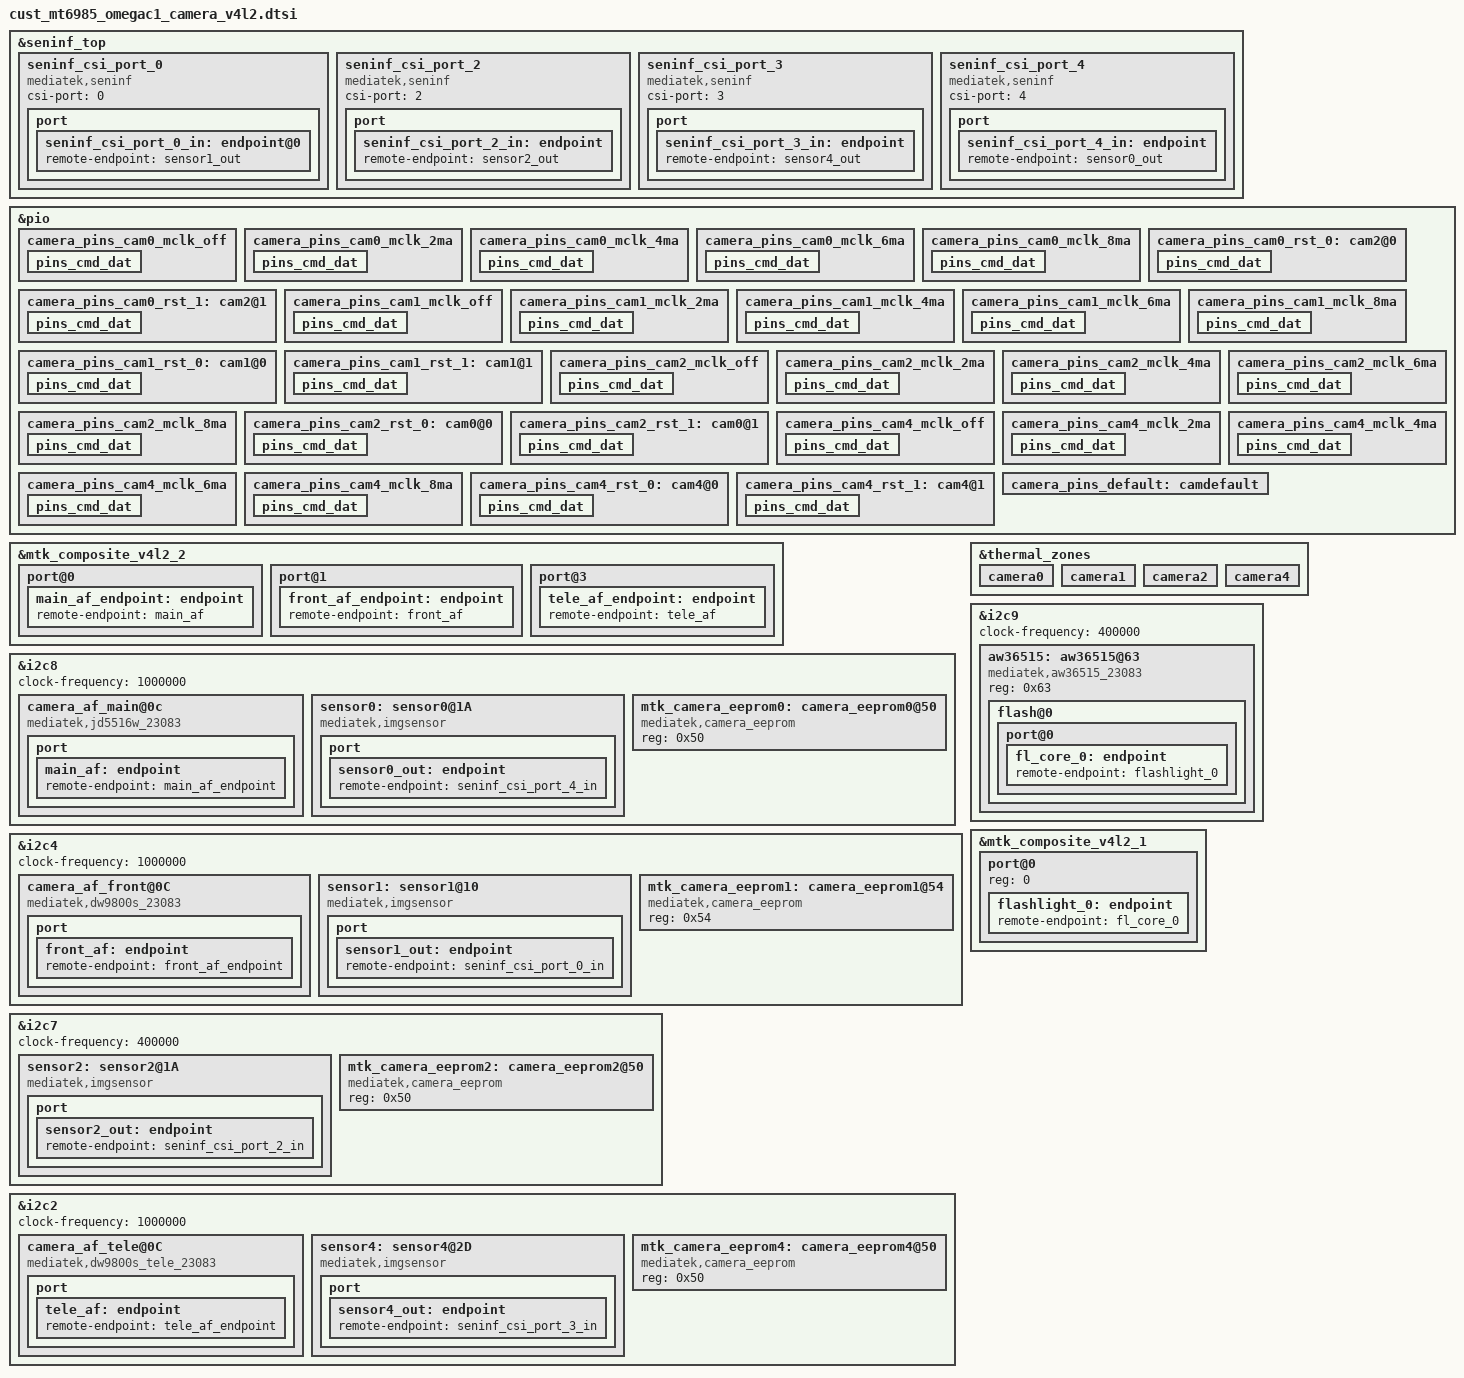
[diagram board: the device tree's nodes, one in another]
// SPDX-License-Identifier: GPL-2.0
/* Copyright (c) 2020 MediaTek Inc. */

#include <dt-bindings/clock/mt6985-clk.h>
#include "mediatek/omegac1-regulator.dtsi"

&seninf_top {
		seninf_csi_port_0: seninf_csi_port_0 {
			compatible = "mediatek,seninf";
			csi-port = "0";
#if 0
			nvmem-cells = <&csi_efuse0>;
			nvmem-cell-names = "rg_csi";
#endif
			port {
				seninf_csi_port_0_in: endpoint@0 {
					remote-endpoint = <&sensor1_out>; //front camera
				};
			};
		};

//		seninf_csi_port_1: seninf_csi_port_1 {
//			compatible = "mediatek,seninf";
//			csi-port = "1";
//#if 0
//			nvmem-cells = <&csi_efuse1>;
//			nvmem-cell-names = "rg_csi";
//#endif
//			port {
//			 	seninf_csi_port_1_in: endpoint {
//			 		remote-endpoint = <&sensor4_out>;
//			 	};
//			 };
//		};

		seninf_csi_port_2: seninf_csi_port_2 {
			compatible = "mediatek,seninf";
			csi-port = "2";
#if 0
			nvmem-cells = <&csi_efuse2>;
			nvmem-cell-names = "rg_csi";
#endif
			port {
				seninf_csi_port_2_in: endpoint {
					remote-endpoint = <&sensor2_out>; //wide camera
				};
			};
		};

		seninf_csi_port_3: seninf_csi_port_3 {
			compatible = "mediatek,seninf";
			csi-port = "3";
#if 0
			nvmem-cells = <&csi_efuse2>;
			nvmem-cell-names = "rg_csi";
#endif
			port {
				seninf_csi_port_3_in: endpoint {
					remote-endpoint = <&sensor4_out>; //tele camera
				};
			};
		};

		seninf_csi_port_4: seninf_csi_port_4 {
			compatible = "mediatek,seninf";
			csi-port = "4";
#if 0
			nvmem-cells = <&csi_efuse2>;
			nvmem-cell-names = "rg_csi";
#endif
			port {
				seninf_csi_port_4_in: endpoint {
					remote-endpoint = <&sensor0_out>; //main camera
				};
			};
		};
};

/* CAMERA GPIO standardization */
&pio {
	/* REAR0 IMX890: MCLK-GPIO208, RESET-GPIO202 */
	camera_pins_cam0_mclk_off: camera_pins_cam0_mclk_off {
		pins_cmd_dat {
			pinmux = <PINMUX_GPIO208__FUNC_GPIO208>;
			drive-strength = <1>;
		};
	};
	camera_pins_cam0_mclk_2ma: camera_pins_cam0_mclk_2ma {
		pins_cmd_dat {
			pinmux = <PINMUX_GPIO208__FUNC_CMMCLK3>;
			drive-strength = <0>;
		};
	};
	camera_pins_cam0_mclk_4ma: camera_pins_cam0_mclk_4ma {
		pins_cmd_dat {
			pinmux = <PINMUX_GPIO208__FUNC_CMMCLK3>;
			drive-strength = <1>;
		};
	};
	camera_pins_cam0_mclk_6ma: camera_pins_cam0_mclk_6ma {
		pins_cmd_dat {
			pinmux = <PINMUX_GPIO208__FUNC_CMMCLK3>;
			drive-strength = <2>;
		};
	};
	camera_pins_cam0_mclk_8ma: camera_pins_cam0_mclk_8ma {
		pins_cmd_dat {
			pinmux = <PINMUX_GPIO208__FUNC_CMMCLK3>;
			drive-strength = <3>;
		};
	};
	camera_pins_cam0_rst_0: cam2@0 {
		pins_cmd_dat {
			pinmux = <PINMUX_GPIO202__FUNC_GPIO202>;
			slew-rate = <1>;
			output-low;
		};
	};
	camera_pins_cam0_rst_1: cam2@1 {
		pins_cmd_dat {
			pinmux = <PINMUX_GPIO202__FUNC_GPIO202>;
			slew-rate = <1>;
			output-high;
		};
	};

	/* FRONT JN5: MCLK-GPIO196, RESET-GPIO148   XVS-GPIO188*/
	camera_pins_cam1_mclk_off: camera_pins_cam1_mclk_off {
		pins_cmd_dat {
			pinmux = <PINMUX_GPIO196__FUNC_GPIO196>;
			drive-strength = <1>;
		};
	};
	camera_pins_cam1_mclk_2ma: camera_pins_cam1_mclk_2ma {
		pins_cmd_dat {
			pinmux = <PINMUX_GPIO196__FUNC_CMMCLK0>;
			drive-strength = <0>;
		};
	};
	camera_pins_cam1_mclk_4ma: camera_pins_cam1_mclk_4ma {
		pins_cmd_dat {
			pinmux = <PINMUX_GPIO196__FUNC_CMMCLK0>;
			drive-strength = <1>;
		};
	};
	camera_pins_cam1_mclk_6ma: camera_pins_cam1_mclk_6ma {
		pins_cmd_dat {
			pinmux = <PINMUX_GPIO196__FUNC_CMMCLK0>;
			drive-strength = <2>;
		};
	};
	camera_pins_cam1_mclk_8ma: camera_pins_cam1_mclk_8ma {
		pins_cmd_dat {
			pinmux = <PINMUX_GPIO196__FUNC_CMMCLK0>;
			drive-strength = <3>;
		};
	};
	camera_pins_cam1_rst_0: cam1@0 {
		pins_cmd_dat {
			pinmux = <PINMUX_GPIO148__FUNC_GPIO148>;
			slew-rate = <1>;
			output-low;
		};
	};
	camera_pins_cam1_rst_1: cam1@1 {
		pins_cmd_dat {
			pinmux = <PINMUX_GPIO148__FUNC_GPIO148>;
			slew-rate = <1>;
			output-high;
		};
	};
//	camera_pins_cam1_pdn_0: cam1@2 {
//		pins_cmd_dat {
//			pinmux = <PINMUX_GPIO188__FUNC_GPIO188>;
//			slew-rate = <1>;
//			output-low;
//		};
//	};
//	camera_pins_cam1_pdn_1: cam1@3 {
//		pins_cmd_dat {
//			pinmux = <PINMUX_GPIO188__FUNC_GPIO188>;
//			slew-rate = <1>;
//			output-high;
//		};
//	};

	/* REAR1 IMX355: MCLK-GPIO198, RESET-GPIO201 */
	camera_pins_cam2_mclk_off: camera_pins_cam2_mclk_off {
		pins_cmd_dat {
			pinmux = <PINMUX_GPIO198__FUNC_GPIO198>;
			drive-strength = <1>;
		};
	};
	camera_pins_cam2_mclk_2ma: camera_pins_cam2_mclk_2ma {
		pins_cmd_dat {
			pinmux = <PINMUX_GPIO198__FUNC_CMMCLK2>;
			drive-strength = <0>;
		};
	};
	camera_pins_cam2_mclk_4ma: camera_pins_cam2_mclk_4ma {
		pins_cmd_dat {
			pinmux = <PINMUX_GPIO198__FUNC_CMMCLK2>;
			drive-strength = <1>;
		};
	};
	camera_pins_cam2_mclk_6ma: camera_pins_cam2_mclk_6ma {
		pins_cmd_dat {
			pinmux = <PINMUX_GPIO198__FUNC_CMMCLK2>;
			drive-strength = <2>;
		};
	};
	camera_pins_cam2_mclk_8ma: camera_pins_cam2_mclk_8ma {
		pins_cmd_dat {
			pinmux = <PINMUX_GPIO198__FUNC_CMMCLK2>;
			drive-strength = <3>;
		};
	};
	camera_pins_cam2_rst_0: cam0@0 {
		pins_cmd_dat {
			pinmux = <PINMUX_GPIO201__FUNC_GPIO201>;
			slew-rate = <1>;
			output-low;
		};
	};
	camera_pins_cam2_rst_1: cam0@1 {
		pins_cmd_dat {
			pinmux = <PINMUX_GPIO201__FUNC_GPIO201>;
			slew-rate = <1>;
			output-high;
		};
	};

	/* REAR2 JN5TELE: MCLK-GPIO197, RESET-GPIO200 */
	camera_pins_cam4_mclk_off: camera_pins_cam4_mclk_off {
		pins_cmd_dat {
			pinmux = <PINMUX_GPIO197__FUNC_GPIO197>;
			drive-strength = <1>;
		};
	};
	camera_pins_cam4_mclk_2ma: camera_pins_cam4_mclk_2ma {
		pins_cmd_dat {
			pinmux = <PINMUX_GPIO197__FUNC_CMMCLK1>;
			drive-strength = <0>;
		};
	};
	camera_pins_cam4_mclk_4ma: camera_pins_cam4_mclk_4ma {
		pins_cmd_dat {
			pinmux = <PINMUX_GPIO197__FUNC_CMMCLK1>;
			drive-strength = <1>;
		};
	};
	camera_pins_cam4_mclk_6ma: camera_pins_cam4_mclk_6ma {
		pins_cmd_dat {
			pinmux = <PINMUX_GPIO197__FUNC_CMMCLK1>;
			drive-strength = <2>;
		};
	};
	camera_pins_cam4_mclk_8ma: camera_pins_cam4_mclk_8ma {
		pins_cmd_dat {
			pinmux = <PINMUX_GPIO197__FUNC_CMMCLK1>;
			drive-strength = <3>;
		};
	};
	camera_pins_cam4_rst_0: cam4@0 {
		pins_cmd_dat {
			pinmux = <PINMUX_GPIO200__FUNC_GPIO200>;
			slew-rate = <1>;
			output-low;
		};
	};
	camera_pins_cam4_rst_1: cam4@1 {
		pins_cmd_dat {
			pinmux = <PINMUX_GPIO200__FUNC_GPIO200>;
			slew-rate = <1>;
			output-high;
		};
	};
	camera_pins_default: camdefault {
	};
};
/* CAMERA GPIO end */

&mtk_composite_v4l2_2 {
	port@0 {
		main_af_endpoint: endpoint {
			remote-endpoint = <&main_af>;
		};
	};
	port@1 {
		front_af_endpoint: endpoint {
			remote-endpoint = <&front_af>;
		};
	};
//	port@2 {
//		wide_af_endpoint: endpoint {
//			remote-endpoint = <&wide_af>;
//		};
//	};
	port@3 {
		tele_af_endpoint: endpoint {
			remote-endpoint = <&tele_af>;
		};
	};
};

&i2c8 {
	status = "okay";
	clock-frequency = <1000000>;
	#address-cells = <1>;
	#size-cells = <0>;

	camera_af_main@0c {
		compatible = "mediatek,jd5516w_23083";
		reg = <0x0c>;
		vin-supply = <&wl28681c_ldo4>;
		port {
			main_af: endpoint {
				remote-endpoint = <&main_af_endpoint>;
			};
		};
	};

	sensor0: sensor0@1A {
		compatible = "mediatek,imgsensor";
		sensor-names = "omegac1main_mipi_raw";
		reg = <0x1A>;
		#thermal-sensor-cells = <0>;

		pinctrl-names = "mclk_off",
				"mclk_2mA",
				"mclk_4mA",
				"mclk_6mA",
				"mclk_8mA",
				"rst_low",
				"rst_high";
		pinctrl-0 = <&camera_pins_cam0_mclk_off>;
		pinctrl-1 = <&camera_pins_cam0_mclk_2ma>;
		pinctrl-2 = <&camera_pins_cam0_mclk_4ma>;
		pinctrl-3 = <&camera_pins_cam0_mclk_6ma>;
		pinctrl-4 = <&camera_pins_cam0_mclk_8ma>;
		pinctrl-5 = <&camera_pins_cam0_rst_0>;
		pinctrl-6 = <&camera_pins_cam0_rst_1>;

		avdd-supply = <&wl28681c_ldo3>;
		avdd1-supply = <&wl28681c_ldo5>;
		dvdd-supply = <&wl28681c_ldo1>;
		dovdd-supply = <&wl28681c_ldo7>;
		afvdd-supply = <&wl28681c_ldo4>;

		clocks = <&topckgen_clk CLK_TOP_UNIVPLL2_192M_D32>,
			<&topckgen_clk CLK_TOP_UNIVPLL2_192M_D16>,
			<&topckgen_clk CLK_TOP_F26M_CK_D2>,
			<&topckgen_clk CLK_TOP_UNIVPLL2_192M_D10>,
			<&topckgen_clk CLK_TOP_UNIVPLL2_192M_D8>,
			<&topckgen_clk CLK_TOP_TCK_26M_MX9>,
			<&topckgen_clk CLK_TOP_UNIVPLL2_D6_D8>,
			<&topckgen_clk CLK_TOP_CAMTG4_SEL>; //PINMUX_GPIO208__FUNC_CMMCLK3
		clock-names = "6", "12", "13", "19.2", "24", "26", "52", "mclk";

		status = "okay";

		port {
			sensor0_out: endpoint {
				remote-endpoint = <&seninf_csi_port_4_in>;
			};
		};
	};

	mtk_camera_eeprom0:camera_eeprom0@50 {
		compatible = "mediatek,camera_eeprom";
		reg = <0x50>;
		status = "okay";
	};
};

&i2c4 {
	status = "okay";
	clock-frequency = <1000000>;
	#address-cells = <1>;
	#size-cells = <0>;

	camera_af_front@0C {
		compatible = "mediatek,dw9800s_23083";
		reg = <0x0C>;
		vin-supply = <&wl28681c_ldo4>;
		port {
			front_af: endpoint {
				remote-endpoint = <&front_af_endpoint>;
			};
		};
	};

	sensor1: sensor1@10 {
		compatible = "mediatek,imgsensor";
		sensor-names = "omegac1front_mipi_raw";
		reg = <0x10>;
		#thermal-sensor-cells = <0>;

		pinctrl-names = "mclk_off",
				"mclk_2mA",
				"mclk_4mA",
				"mclk_6mA",
				"mclk_8mA",
				"rst_low",
				"rst_high";
//				"pdn_low",
//				"pdn_high";
		pinctrl-0 = <&camera_pins_cam1_mclk_off>;
		pinctrl-1 = <&camera_pins_cam1_mclk_2ma>;
		pinctrl-2 = <&camera_pins_cam1_mclk_4ma>;
		pinctrl-3 = <&camera_pins_cam1_mclk_6ma>;
		pinctrl-4 = <&camera_pins_cam1_mclk_8ma>;
		pinctrl-5 = <&camera_pins_cam1_rst_0>;
		pinctrl-6 = <&camera_pins_cam1_rst_1>;
//		pinctrl-7 = <&camera_pins_cam1_pdn_0>;
//		pinctrl-8 = <&camera_pins_cam1_pdn_1>;

		avdd-supply = <&wl28681c_ldo6>;
		dvdd-supply = <&wl28681c_ldo2>;
		dovdd-supply = <&wl28681c_ldo7>;
		afvdd-supply = <&wl28681c_ldo4>;

		clocks = <&topckgen_clk CLK_TOP_UNIVPLL_192M_D32>,
			<&topckgen_clk CLK_TOP_UNIVPLL_192M_D16>,
			<&topckgen_clk CLK_TOP_F26M_CK_D2>,
			<&topckgen_clk CLK_TOP_UNIVPLL_192M_D10>,
			<&topckgen_clk CLK_TOP_UNIVPLL_192M_D8>,
			<&topckgen_clk CLK_TOP_UNIVPLL_D6_D16>,
			<&topckgen_clk CLK_TOP_UNIVPLL_D6_D8>,
			<&vlp_cksys_clk CLK_VLP_CK_CAMTG_VLP_SEL>;  //PINMUX_GPIO196__FUNC_CMMCLK0
		clock-names = "6", "12", "13", "19.2", "24", "26", "52", "mclk";

		status = "okay";
//		/*If this project use explorer AON driver, set this flag as ture.*/
//		support_explorer_aon = "true";
//		aon-irq-gpio = <&pio 188 0x0>;

		port {
			sensor1_out: endpoint {
				remote-endpoint = <&seninf_csi_port_0_in>;
			};
		};
	};

	mtk_camera_eeprom1:camera_eeprom1@54 {
		compatible = "mediatek,camera_eeprom";
		reg = <0x54>;
		status = "okay";
	};
};

&i2c7 {
	status = "okay";
	clock-frequency = <400000>;

	sensor2: sensor2@1A {
		compatible = "mediatek,imgsensor";
		sensor-names = "omegac1wide_mipi_raw";
		reg = <0x1A>;
		#thermal-sensor-cells = <0>;

		pinctrl-names = "mclk_off",
				"mclk_2mA",
				"mclk_4mA",
				"mclk_6mA",
				"mclk_8mA",
				"rst_low",
				"rst_high";
		pinctrl-0 = <&camera_pins_cam2_mclk_off>;
		pinctrl-1 = <&camera_pins_cam2_mclk_2ma>;
		pinctrl-2 = <&camera_pins_cam2_mclk_4ma>;
		pinctrl-3 = <&camera_pins_cam2_mclk_6ma>;
		pinctrl-4 = <&camera_pins_cam2_mclk_8ma>;
		pinctrl-5 = <&camera_pins_cam2_rst_0>;
		pinctrl-6 = <&camera_pins_cam2_rst_1>;

		avdd-supply = <&wl28681c_ldo3>;
		dvdd-supply = <&mt6373_vrf13_aif>;
		dovdd-supply = <&wl28681c_ldo7>;

		clocks = <&topckgen_clk CLK_TOP_UNIVPLL2_192M_D32>,
			<&topckgen_clk CLK_TOP_UNIVPLL2_192M_D16>,
			<&topckgen_clk CLK_TOP_F26M_CK_D2>,
			<&topckgen_clk CLK_TOP_UNIVPLL2_192M_D10>,
			<&topckgen_clk CLK_TOP_UNIVPLL2_192M_D8>,
			<&topckgen_clk CLK_TOP_TCK_26M_MX9>,
			<&topckgen_clk CLK_TOP_UNIVPLL2_D6_D8>,
			<&topckgen_clk CLK_TOP_CAMTG3_SEL>;    //PINMUX_GPIO198__FUNC_CMMCLK2
		clock-names = "6", "12", "13", "19.2", "24", "26", "52", "mclk";

		status = "okay";

		port {
			sensor2_out: endpoint {
				remote-endpoint = <&seninf_csi_port_2_in>;
			};
		};
	};

	mtk_camera_eeprom2:camera_eeprom2@50 {
		compatible = "mediatek,camera_eeprom";
		reg = <0x50>;
		status = "okay";
	};
};

&i2c2 {
	status = "okay";
	clock-frequency = <1000000>;
	#address-cells = <1>;
	#size-cells = <0>;

	camera_af_tele@0C {
		compatible = "mediatek,dw9800s_tele_23083";
		reg = <0x0C>;
		vin-supply = <&wl28681c_ldo4>;
		port {
			tele_af: endpoint {
				remote-endpoint = <&tele_af_endpoint>;
			};
		};
	};

	sensor4: sensor4@2D {
		compatible = "mediatek,imgsensor";
		sensor-names = "omegac1tele_mipi_raw";
		reg = <0x2D>;
		#thermal-sensor-cells = <0>;

		pinctrl-names = "mclk_off",
				"mclk_2mA",
				"mclk_4mA",
				"mclk_6mA",
				"mclk_8mA",
				"rst_low",
				"rst_high";
		pinctrl-0 = <&camera_pins_cam4_mclk_off>;
		pinctrl-1 = <&camera_pins_cam4_mclk_2ma>;
		pinctrl-2 = <&camera_pins_cam4_mclk_4ma>;
		pinctrl-3 = <&camera_pins_cam4_mclk_6ma>;
		pinctrl-4 = <&camera_pins_cam4_mclk_8ma>;
		pinctrl-5 = <&camera_pins_cam4_rst_0>;
		pinctrl-6 = <&camera_pins_cam4_rst_1>;

		avdd-supply = <&wl28681c_ldo6>;
		dvdd-supply = <&wl28681c_ldo2>;
		dovdd-supply = <&wl28681c_ldo7>;
		afvdd-supply = <&wl28681c_ldo4>;

		clocks = <&topckgen_clk CLK_TOP_UNIVPLL2_192M_D32>,
			<&topckgen_clk CLK_TOP_UNIVPLL2_192M_D16>,
			<&topckgen_clk CLK_TOP_F26M_CK_D2>,
			<&topckgen_clk CLK_TOP_UNIVPLL2_192M_D10>,
			<&topckgen_clk CLK_TOP_UNIVPLL2_192M_D8>,
			<&topckgen_clk CLK_TOP_TCK_26M_MX9>,
			<&topckgen_clk CLK_TOP_UNIVPLL2_D6_D8>,
			<&topckgen_clk CLK_TOP_CAMTG2_SEL>;  //PINMUX_GPIO197__FUNC_CMMCLK1
		clock-names = "6", "12", "13", "19.2", "24", "26", "52", "mclk";

		status = "okay";

		port {
			sensor4_out: endpoint {
				remote-endpoint = <&seninf_csi_port_3_in>;
			};
		};
	};

	mtk_camera_eeprom4:camera_eeprom4@50 {
		compatible = "mediatek,camera_eeprom";
		reg = <0x50>;
		status = "okay";
	};
};

&thermal_zones {
	camera0: camera0 {
		polling-delay = <0>; /* milliseconds */
		polling-delay-passive = <0>; /* milliseconds */
		thermal-sensors = <&sensor0>;
	};
	camera1: camera1 {
		polling-delay = <0>; /* milliseconds */
		polling-delay-passive = <0>; /* milliseconds */
		thermal-sensors = <&sensor1>;
	};
	camera2: camera2 {
		polling-delay = <0>; /* milliseconds */
		polling-delay-passive = <0>; /* milliseconds */
		thermal-sensors = <&sensor2>;
	};
	camera4: camera4 {
		polling-delay = <0>; /* milliseconds */
		polling-delay-passive = <0>; /* milliseconds */
		thermal-sensors = <&sensor4>;
	};
};

/*Flash light*/
&i2c9 {
	clock-frequency = <400000>;
	#address-cells = <1>;
	#size-cells = <0>;
    aw36515:aw36515@63 {
        compatible = "mediatek,aw36515_23083";
        reg = <0x63>;
        #cooling-cells = <2>;
        status = "okay";
        flash@0{
            reg = <0>;
            type = <0>;
            ct = <0>;
            part = <0>;
            port@0 {
                fl_core_0: endpoint {
                    remote-endpoint = <&flashlight_0>;
                };
            };
        };
    };
};

&mtk_composite_v4l2_1 {
	#address-cells = <1>;
	#size-cells = <0>;
	port@0 {
		reg = <0>;
		flashlight_0: endpoint {
			remote-endpoint = <&fl_core_0>;
		};
	};
};

